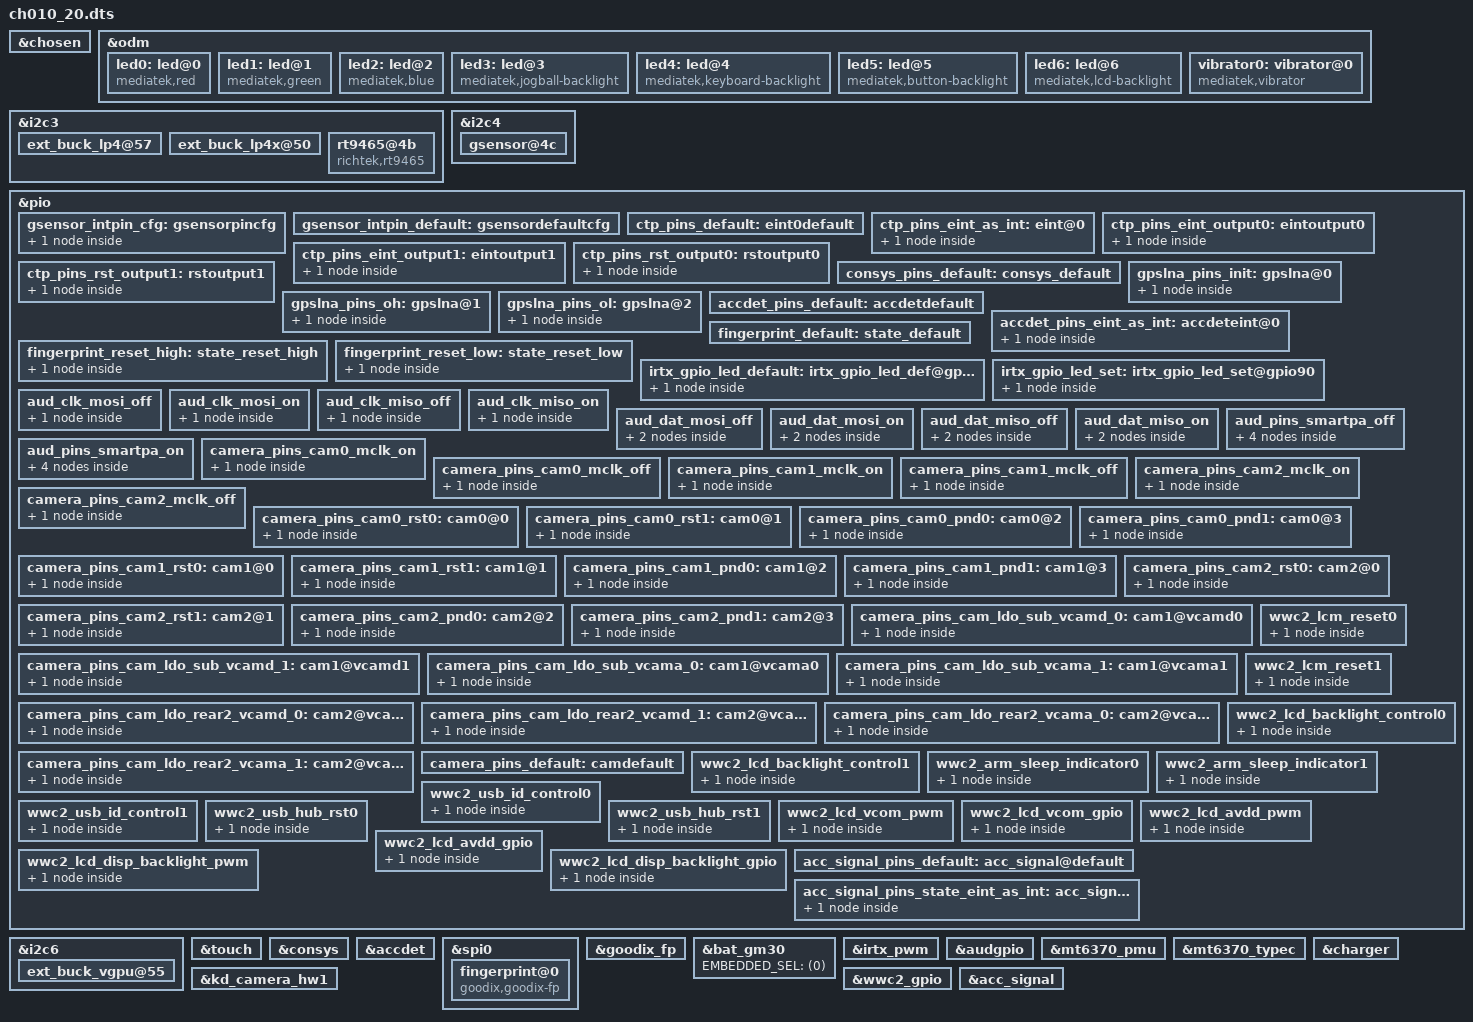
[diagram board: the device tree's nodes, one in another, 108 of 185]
#include <dt-bindings/interrupt-controller/arm-gic.h>
#include <dt-bindings/interrupt-controller/irq.h>
#include <dt-bindings/pinctrl/mt6765-pinfunc.h>
#include <dt-bindings/clock/mt6765-clk.h>

/dts-v1/;
/plugin/;

/* chosen */
&chosen {
	bootargs = "console=tty0 console=ttyS0,921600n1\
root=/dev/ram initrd=0x45000000,0x1000000 loglevel=8 \
androidboot.selinux=permissive androidboot.hardware=mt6765 \
initcall_debug=1 maxcpus=1";

	/* fpga may has no lk, we need to specify display info here */
	/* fb buffer is reserved using this dts by memory node above */
	atag,videolfb-fb_base_h = <0x0>;
	atag,videolfb-fb_base_l = <0x5e605000>;
	atag,videolfb-islcmfound = <1>;
	/* because no lk, so lcm is not inited */
	atag,videolfb-islcm_inited = <0>;
	atag,videolfb-fps= <6000>;
	atag,videolfb-vramSize= <0x017bb000>;
	atag,videolfb-lcmname= "nt35695B_fhd_dsi_cmd_auo_rt5081_drv";
};

&odm {
	led0:led@0 {
		compatible = "mediatek,red";
		led_mode = <0>;
		data = <1>;
		pwm_config = <0 0 0 0 0>;
	};
	led1:led@1 {
		compatible = "mediatek,green";
		led_mode = <0>;
		data = <1>;
		pwm_config = <0 0 0 0 0>;
	};
	led2:led@2 {
		compatible = "mediatek,blue";
		led_mode = <0>;
		data = <1>;
		pwm_config = <0 0 0 0 0>;
	};
	led3:led@3 {
		compatible = "mediatek,jogball-backlight";
		led_mode = <0>;
		data = <1>;
		pwm_config = <0 0 0 0 0>;
	};
	led4:led@4 {
		compatible = "mediatek,keyboard-backlight";
		led_mode = <0>;
		data = <1>;
		pwm_config = <0 0 0 0 0>;
	};
	led5:led@5 {
		compatible = "mediatek,button-backlight";
		led_mode = <0>;
		data = <1>;
		pwm_config = <0 0 0 0 0>;
	};
	led6:led@6 {
		compatible = "mediatek,lcd-backlight";
		led_mode = <5>;
		data = <1>;
		pwm_config = <0 3 0 0 0>;
		led_enable_gpio = <&pio 44 0>;
	};
	vibrator0:vibrator@0 {
		compatible = "mediatek,vibrator";
		vib_timer = <25>;
		vib_limit = <9>;
		vib_vol= <9>;
	};
};

&i2c3 {
	ext_buck_lp4@57 {
		regulator-name ="ext_buck_vdd2";
		regulator-min-microvolt = <300000>;
		regulator-max-microvolt = <1300000>;
		vsel_pin = <0>;
	};

	ext_buck_lp4x@50 {
		regulator-name ="ext_buck_vddq";
		regulator-min-microvolt = <300000>;
		regulator-max-microvolt = <1300000>;
		vsel_pin = <1>;
	};
};

&i2c4 {
/*  start sensor */
	gsensor@4c {
		pinctrl-names = "pin_default", "pin_cfg";
		pinctrl-0 = <&gsensor_intpin_default>;
		pinctrl-1 = <&gsensor_intpin_cfg>;
		status = "okay";

		i2c_num	= <4>;
		i2c_addr = <0x4c 0 0 0>;
		direction = <1>;
		power_id = <0xffff>;
		power_vol = <0>;
		firlen = <0>;
		is_batch_supported = <0>;
	};
/* end sensor */
};

/* sensor gpio standization */
&pio {
	gsensor_intpin_cfg: gsensorpincfg {

		pins_cmd_dat {
			pinmux = <PINMUX_GPIO4__FUNC_GPIO4>;
			slew-rate = <0>;
			bias-pull-up = <00>;
		};
	};

	gsensor_intpin_default: gsensordefaultcfg {

	};
};
/* sensor end */

&i2c6 {
	ext_buck_vgpu@55 {
		regulator-name ="ext_buck_vgpu";
		regulator-min-microvolt = <300000>;
		regulator-max-microvolt = <1300000>;
		vsel_pin = <2>;
	};
};
/* TOUCH start */
&touch {
	tpd-resolution = <1024 600>;
	use-tpd-button = <1>;
	tpd-key-num = <6>;
	tpd-key-local= <105 105 105 105 105 105>;
	tpd-key-dim-local = <1080 110 30 30 1080 180 30 30 1080 240 30 30 1080 320 30 30 1080 390 30 30 0 0 0 0>;
	tpd-max-touch-num = <6>;
	tpd-filter-enable = <1>;
	tpd-filter-pixel-density = <106>;
	tpd-filter-custom-prameters = <0 0 0 0 0 0 0 0 0 0 0 0>;
	tpd-filter-custom-speed = <0 0 0>;
	pinctrl-names = "default", "state_eint_as_int", "state_eint_output0",
		"state_eint_output1", "state_rst_output0", "state_rst_output1";
	pinctrl-0 = <&ctp_pins_default>;
	pinctrl-1 = <&ctp_pins_eint_as_int>;
	pinctrl-2 = <&ctp_pins_eint_output0>;
	pinctrl-3 = <&ctp_pins_eint_output1>;
	pinctrl-4 = <&ctp_pins_rst_output0>;
	pinctrl-5 = <&ctp_pins_rst_output1>;
	status = "okay";
};
&pio {
	ctp_pins_default: eint0default {
	};
	ctp_pins_eint_as_int: eint@0 {
		pins_cmd_dat {
			pinmux = <PINMUX_GPIO0__FUNC_GPIO0>;
			slew-rate = <0>;
			bias-disable;
		};
	};
	ctp_pins_eint_output0: eintoutput0 {
		pins_cmd_dat {
			pinmux = <PINMUX_GPIO0__FUNC_GPIO0>;
			slew-rate = <1>;
			output-low;
		};
	};
	ctp_pins_eint_output1: eintoutput1 {
		pins_cmd_dat {
			pinmux = <PINMUX_GPIO0__FUNC_GPIO0>;
			slew-rate = <1>;
			output-high;
		};
	};
	ctp_pins_rst_output0: rstoutput0 {
		pins_cmd_dat {
			pinmux = <PINMUX_GPIO174__FUNC_GPIO174>;
			slew-rate = <1>;
			output-low;
		};
	};
	ctp_pins_rst_output1: rstoutput1 {
		pins_cmd_dat {
			pinmux = <PINMUX_GPIO174__FUNC_GPIO174>;
			slew-rate = <1>;
			output-high;
		};
	};
};
/* TOUCH end */

/* CONSYS GPIO standardization */
&pio {
	consys_pins_default: consys_default {
	};
	gpslna_pins_init: gpslna@0 {
		pins_cmd_dat {
			pinmux = <PINMUX_GPIO178__FUNC_GPIO178>;
			slew-rate = <0>;
			bias-disable;
			output-low;
		};
	};
	gpslna_pins_oh: gpslna@1 {
		pins_cmd_dat {
			pinmux = <PINMUX_GPIO178__FUNC_GPIO178>;
			slew-rate = <1>;
			output-high;
		};
	};
	gpslna_pins_ol: gpslna@2 {
		pins_cmd_dat {
			pinmux = <PINMUX_GPIO178__FUNC_GPIO178>;
			slew-rate = <1>;
			output-low;
		};
	};
};
&consys {
	pinctrl-names = "default", "gps_lna_state_init",
		"gps_lna_state_oh", "gps_lna_state_ol";
	pinctrl-0 = <&consys_pins_default>;
	pinctrl-1 = <&gpslna_pins_init>;
	pinctrl-2 = <&gpslna_pins_oh>;
	pinctrl-3 = <&gpslna_pins_ol>;
	status = "okay";
};
/* CONSYS end */

/* accdet start */
&accdet {
	accdet-mic-vol = <6>;
	headset-mode-setting = <0x500 0x500 1 0x1f0 0x800 0x800 0x20 0x44>;
	accdet-plugout-debounce = <1>;
	accdet-mic-mode = <1>;
	headset-eint-level-pol = <8>;
	headset-three-key-threshold = <0 80 220 400>;
	headset-three-key-threshold-CDD = <0 121 192 600>;
	headset-four-key-threshold = <0 58 121 192 400>;
	pinctrl-names = "default", "state_eint_as_int";
	pinctrl-0 = <&accdet_pins_default>;
	pinctrl-1 = <&accdet_pins_eint_as_int>;
	status = "okay";
};
&pio {
	accdet_pins_default: accdetdefault {
	};
	accdet_pins_eint_as_int: accdeteint@0 {
		pins_cmd_dat {
			pinmux = <PINMUX_GPIO9__FUNC_GPIO9>;
			slew-rate = <0>;
			bias-disable;
		};
	};
};
/* accdet end */

/* FINGERPRINT start */
&spi0 {
	#address-cells = <1>;
	#size-cells = <0>;
	fingerprint@0 {
		compatible = "goodix,goodix-fp";
		reg = <0>;
		spi-max-frequency = <8000000>;
		netlink-event = <30>;
		status = "okay";
	};
};

&goodix_fp {
	pinctrl-names = "default", "reset_high", "reset_low";
	pinctrl-0 = <&fingerprint_default>;
	pinctrl-1 = <&fingerprint_reset_high>;
	pinctrl-2 = <&fingerprint_reset_low>;
	status = "okay";
};

&pio {
	fingerprint_default: state_default {
	};
	fingerprint_reset_high: state_reset_high {
		pins_cmd_dat {
			pinmux = <PINMUX_GPIO172__FUNC_GPIO172>;
			slew-rate = <1>;
			output-high;
		};
	};
	fingerprint_reset_low: state_reset_low {
		pins_cmd_dat {
			pinmux = <PINMUX_GPIO172__FUNC_GPIO172>;
			slew-rate = <1>;
			output-low;
		};
	};
};
/* FINGERPRINT end */

/* battery end */
&bat_gm30 {
	EMBEDDED_SEL = <(0)>;
};
/* battery end */

/* IRTX GPIO end */
&irtx_pwm {
	pinctrl-names = "irtx_gpio_led_default", "irtx_gpio_led_set";
	pinctrl-0 = <&irtx_gpio_led_default>;
	pinctrl-1 = <&irtx_gpio_led_set>;
	status = "okay";
};
&pio {
	irtx_gpio_led_default:irtx_gpio_led_def@gpio90 {
		pins_cmd_dat {
			pinmux = <PINMUX_GPIO90__FUNC_GPIO90>;
			slew-rate = <1>;
			bias-disable;
			output-low;
			input-schmitt-enable = <0>;
		};
	};

	irtx_gpio_led_set:irtx_gpio_led_set@gpio90 {
		pins_cmd_dat {
			pinmux = <PINMUX_GPIO90__FUNC_PWM0>;
			slew-rate = <1>;
			output-high;
		};
	};
};
/* IRTX GPIO Settings -End */

/* AUDIO GPIO standardization */
&audgpio {
	pinctrl-names = "aud_clk_mosi_off",
			"aud_clk_mosi_on",
			"aud_clk_miso_off",
			"aud_clk_miso_on",
			"aud_dat_mosi_off",
			"aud_dat_mosi_on",
			"aud_dat_miso_off",
			"aud_dat_miso_on",
			"aud_smartpa_off",
			"aud_smartpa_on";
	pinctrl-0 = <&aud_clk_mosi_off>;
	pinctrl-1 = <&aud_clk_mosi_on>;
	pinctrl-2 = <&aud_clk_miso_off>;
	pinctrl-3 = <&aud_clk_miso_on>;
	pinctrl-4 = <&aud_dat_mosi_off>;
	pinctrl-5 = <&aud_dat_mosi_on>;
	pinctrl-6 = <&aud_dat_miso_off>;
	pinctrl-7 = <&aud_dat_miso_on>;
	pinctrl-8 = <&aud_pins_smartpa_off>;
	pinctrl-9 = <&aud_pins_smartpa_on>;
	status = "okay";
};

&pio {
	aud_clk_mosi_off: aud_clk_mosi_off {
		pins_cmd0_dat {
			pinmux = <PINMUX_GPIO136__FUNC_GPIO136>;
		};
	};

	aud_clk_mosi_on: aud_clk_mosi_on {
		pins_cmd0_dat {
			pinmux = <PINMUX_GPIO136__FUNC_AUD_CLK_MOSI>;
		};
	};

	aud_clk_miso_off: aud_clk_miso_off {
		pins_cmd0_dat {
			pinmux = <PINMUX_GPIO140__FUNC_GPIO140>;
		};
	};

	aud_clk_miso_on: aud_clk_miso_on {
		pins_cmd0_dat {
			pinmux = <PINMUX_GPIO140__FUNC_AUD_CLK_MISO>;
		};
	};

	aud_dat_mosi_off: aud_dat_mosi_off {
		pins_cmd1_dat {
			pinmux = <PINMUX_GPIO138__FUNC_GPIO138>;
			input-enable;
			slew-rate = <0>;
			bias-disable;
		};
		pins_cmd2_dat {
			pinmux = <PINMUX_GPIO139__FUNC_GPIO139>;
			input-enable;
			slew-rate = <0>;
			bias-disable;
		};
	};

	aud_dat_mosi_on: aud_dat_mosi_on {
		pins_cmd1_dat {
			pinmux = <PINMUX_GPIO138__FUNC_AUD_DAT_MOSI0>;
		};
		pins_cmd2_dat {
			pinmux = <PINMUX_GPIO139__FUNC_AUD_DAT_MOSI1>;
		};
	};

	aud_dat_miso_off: aud_dat_miso_off {
		pins_cmd1_dat {
			pinmux = <PINMUX_GPIO142__FUNC_GPIO142>;
			input-enable;
			slew-rate = <0>;
			bias-disable;
		};
		pins_cmd2_dat {
			pinmux = <PINMUX_GPIO143__FUNC_GPIO143>;
			input-enable;
			slew-rate = <0>;
			bias-disable;
		};
	};

	aud_dat_miso_on: aud_dat_miso_on {
		pins_cmd1_dat {
			pinmux = <PINMUX_GPIO142__FUNC_AUD_DAT_MISO0>;
		};
		pins_cmd2_dat {
			pinmux = <PINMUX_GPIO143__FUNC_AUD_DAT_MISO1>;
		};
	};

	aud_pins_smartpa_off: aud_pins_smartpa_off {
		pins_cmd0_dat {
			pinmux = <PINMUX_GPIO17__FUNC_GPIO17>;
		};
		pins_cmd1_dat {
			pinmux = <PINMUX_GPIO18__FUNC_GPIO18>;
		};
		pins_cmd2_dat {
			pinmux = <PINMUX_GPIO19__FUNC_GPIO19>;
		};
		pins_cmd3_dat {
			pinmux = <PINMUX_GPIO20__FUNC_GPIO20>;
		};
	};

	aud_pins_smartpa_on: aud_pins_smartpa_on {
		pins_cmd0_dat {
			pinmux = <PINMUX_GPIO17__FUNC_I2S0_DI>;
		};
		pins_cmd1_dat {
			pinmux = <PINMUX_GPIO18__FUNC_I2S3_BCK>;
		};
		pins_cmd2_dat {
			pinmux = <PINMUX_GPIO19__FUNC_I2S3_LRCK>;
		};
		pins_cmd3_dat {
			pinmux = <PINMUX_GPIO20__FUNC_I2S3_DO>;
		};
	};
};
/* AUDIO end */

&mt6370_pmu {
	mt6370,intr_gpio_num = <11>; /* direct defined GPIO num */
	mt6370,intr_gpio = <&pio 11 0x0>;
};

&mt6370_typec {
	mt6370pd,intr_gpio_num = <41>; /* direct defined GPIO num */
	mt6370pd,intr_gpio = <&pio 41 0x0>;
};

&charger {
	algorithm_name = "DualSwitchCharging";
	chg1_ta_ac_charger_current = <2000000>;
	chg2_ta_ac_charger_current = <2000000>;
};

&i2c3 {
	rt9465@4b {
		compatible = "richtek,rt9465";
		reg = <0x4b>;
		status = "okay";
		rt,en_gpio_num = <176>;
		rt,en_gpio = <&pio 176 0x0>;
		rt,intr_gpio_num = <23>; /* direct defined GPIO num */
		rt,intr_gpio = <&pio 23 0x0>;
		interrupt-names = "wdtmri";
		charger_name = "secondary_chg";
		ichg = <1500000>; /* uA */
		mivr = <4500000>; /* uV */
		cv = <4550000>; /* uV */
		ieoc = <700000>; /* uA */
		safety_timer = <12>; /* hour */
		en_st; /* safety timer */
		/* en_te; */
		en_wdt;
	};
};

&pio {
	camera_pins_cam0_mclk_on: camera_pins_cam0_mclk_on {
		pins_cmd_dat {
			pinmux = <PINMUX_GPIO100__FUNC_CMMCLK1>;
		};
	};
	camera_pins_cam0_mclk_off: camera_pins_cam0_mclk_off {
		pins_cmd_dat {
			pinmux = <PINMUX_GPIO100__FUNC_GPIO100>;
		};
	};
	camera_pins_cam1_mclk_on: camera_pins_cam1_mclk_on {
		pins_cmd_dat {
			pinmux = <PINMUX_GPIO99__FUNC_CMMCLK0>;
		};
	};
	camera_pins_cam1_mclk_off: camera_pins_cam1_mclk_off {
		pins_cmd_dat {
			pinmux = <PINMUX_GPIO99__FUNC_GPIO99>;
		};
	};
	camera_pins_cam2_mclk_on: camera_pins_cam2_mclk_on {
		pins_cmd_dat {
			pinmux = <PINMUX_GPIO99__FUNC_CMMCLK0>;
		};
	};
	camera_pins_cam2_mclk_off: camera_pins_cam2_mclk_off {
		pins_cmd_dat {
			pinmux = <PINMUX_GPIO99__FUNC_GPIO99>;
		};
	};
	camera_pins_cam0_rst0: cam0@0 {
		pins_cmd_dat {
			pinmux = <PINMUX_GPIO102__FUNC_GPIO102>;
			slew-rate = <1>;
			output-low;
		};
	};
	camera_pins_cam0_rst1: cam0@1 {
		pins_cmd_dat {
			pinmux = <PINMUX_GPIO102__FUNC_GPIO102>;
			slew-rate = <1>;
			output-high;
		};
	};
	camera_pins_cam0_pnd0: cam0@2 {
		pins_cmd_dat {
			pinmux = <PINMUX_GPIO98__FUNC_GPIO98>;
			slew-rate = <1>;
			output-low;
		};
	};
	camera_pins_cam0_pnd1: cam0@3 {
		pins_cmd_dat {
			pinmux = <PINMUX_GPIO98__FUNC_GPIO98>;
			slew-rate = <1>;
			output-high;
		};
	};
	camera_pins_cam1_rst0: cam1@0 {
		pins_cmd_dat {
			pinmux = <PINMUX_GPIO101__FUNC_GPIO101>;
			slew-rate = <1>;
			output-low;
		};
	};
	camera_pins_cam1_rst1: cam1@1 {
		pins_cmd_dat {
			pinmux = <PINMUX_GPIO101__FUNC_GPIO101>;
			slew-rate = <1>;
			output-high;
		};
	};
	camera_pins_cam1_pnd0: cam1@2 {
		pins_cmd_dat {
			pinmux = <PINMUX_GPIO97__FUNC_GPIO97>;
			slew-rate = <1>;
			output-low;
		};
	};
	camera_pins_cam1_pnd1: cam1@3 {
		pins_cmd_dat {
			pinmux = <PINMUX_GPIO97__FUNC_GPIO97>;
			slew-rate = <1>;
			output-high;
		};
	};
	camera_pins_cam2_rst0: cam2@0 {
		pins_cmd_dat {
			pinmux = <PINMUX_GPIO101__FUNC_GPIO101>;
			slew-rate = <1>;
			output-low;
		};
	};
	camera_pins_cam2_rst1: cam2@1 {
		pins_cmd_dat {
			pinmux = <PINMUX_GPIO101__FUNC_GPIO101>;
			slew-rate = <1>;
			output-high;
		};
	};
	camera_pins_cam2_pnd0: cam2@2 {
		pins_cmd_dat {
			pinmux = <PINMUX_GPIO97__FUNC_GPIO97>;
			slew-rate = <1>;
			output-low;
		};
	};
	camera_pins_cam2_pnd1: cam2@3 {
		pins_cmd_dat {
			pinmux = <PINMUX_GPIO97__FUNC_GPIO97>;
			slew-rate = <1>;
			output-high;
		};
	};
	camera_pins_cam_ldo_sub_vcamd_0: cam1@vcamd0 {
		pins_cmd_dat {
			pinmux = <PINMUX_GPIO108__FUNC_GPIO108>;
			slew-rate = <1>;
			output-low;
		};
	};
	camera_pins_cam_ldo_sub_vcamd_1: cam1@vcamd1 {
		pins_cmd_dat {
			pinmux = <PINMUX_GPIO108__FUNC_GPIO108>;
			slew-rate = <1>;
			output-high;
		};
	};
	camera_pins_cam_ldo_sub_vcama_0: cam1@vcama0 {
		pins_cmd_dat {
			pinmux = <PINMUX_GPIO109__FUNC_GPIO109>;
			slew-rate = <1>;
			output-low;
		};
	};
	camera_pins_cam_ldo_sub_vcama_1: cam1@vcama1 {
		pins_cmd_dat {
			pinmux = <PINMUX_GPIO109__FUNC_GPIO109>;
			slew-rate = <1>;
			output-high;
		};
	};
	camera_pins_cam_ldo_rear2_vcamd_0: cam2@vcamd0 {
		pins_cmd_dat {
			pinmux = <PINMUX_GPIO108__FUNC_GPIO108>;
			slew-rate = <1>;
			output-low;
		};
	};
	camera_pins_cam_ldo_rear2_vcamd_1: cam2@vcamd1 {
		pins_cmd_dat {
			pinmux = <PINMUX_GPIO108__FUNC_GPIO108>;
			slew-rate = <1>;
			output-high;
		};
	};
	camera_pins_cam_ldo_rear2_vcama_0: cam2@vcama0 {
		pins_cmd_dat {
			pinmux = <PINMUX_GPIO109__FUNC_GPIO109>;
			slew-rate = <1>;
			output-low;
		};
	};
	camera_pins_cam_ldo_rear2_vcama_1: cam2@vcama1 {
		pins_cmd_dat {
			pinmux = <PINMUX_GPIO109__FUNC_GPIO109>;
			slew-rate = <1>;
			output-high;
		};
	};
	camera_pins_default: camdefault {
	};

};

&kd_camera_hw1 {
	pinctrl-names = "default",
			"cam0_rst0",
			"cam0_rst1",
			"cam0_pnd0",
			"cam0_pnd1",
			"cam1_rst0",
			"cam1_rst1",
			"cam1_pnd0",
			"cam1_pnd1",
			"cam2_rst0",
			"cam2_rst1",
			"cam2_pnd0",
			"cam2_pnd1",
			"cam1_vcamd_on",
			"cam1_vcamd_off",
			"cam1_vcama_on",
			"cam1_vcama_off",
			"cam2_vcamd_on",
			"cam2_vcamd_off",
			"cam2_vcama_on",
			"cam2_vcama_off",
			"cam0_mclk_on",
			"cam0_mclk_off",
			"cam1_mclk_on",
			"cam1_mclk_off",
			"cam2_mclk_on",
			"cam2_mclk_off";

	pinctrl-0 = <&camera_pins_default>;
	pinctrl-1 = <&camera_pins_cam0_rst0>;
	pinctrl-2 = <&camera_pins_cam0_rst1>;
	pinctrl-3 = <&camera_pins_cam0_pnd0>;
	pinctrl-4 = <&camera_pins_cam0_pnd1>;
	pinctrl-5 = <&camera_pins_cam1_rst0>;
	pinctrl-6 = <&camera_pins_cam1_rst1>;
	pinctrl-7 = <&camera_pins_cam1_pnd0>;
	pinctrl-8 = <&camera_pins_cam1_pnd1>;
	pinctrl-9 = <&camera_pins_cam2_rst0>;
	pinctrl-10 = <&camera_pins_cam2_rst1>;
	pinctrl-11 = <&camera_pins_cam2_pnd0>;
	pinctrl-12 = <&camera_pins_cam2_pnd1>;
	pinctrl-13 = <&camera_pins_cam_ldo_sub_vcamd_1>;
	pinctrl-14 = <&camera_pins_cam_ldo_sub_vcamd_0>;
	pinctrl-15 = <&camera_pins_cam_ldo_sub_vcama_1>;
	pinctrl-16 = <&camera_pins_cam_ldo_sub_vcama_0>;
	pinctrl-17 = <&camera_pins_cam_ldo_rear2_vcamd_1>;
	pinctrl-18 = <&camera_pins_cam_ldo_rear2_vcamd_0>;
	pinctrl-19 = <&camera_pins_cam_ldo_rear2_vcama_1>;
	pinctrl-20 = <&camera_pins_cam_ldo_rear2_vcama_0>;
	pinctrl-21 = <&camera_pins_cam0_mclk_on>;
	pinctrl-22 = <&camera_pins_cam0_mclk_off>;
	pinctrl-23 = <&camera_pins_cam1_mclk_on>;
	pinctrl-24 = <&camera_pins_cam1_mclk_off>;
	pinctrl-25 = <&camera_pins_cam2_mclk_on>;
	pinctrl-26 = <&camera_pins_cam2_mclk_off>;
	status = "okay";

};

&pio {
	wwc2_lcm_reset0: wwc2_lcm_reset0 {
		pins_cmd_dat {
			pinmux = <PINMUX_GPIO45__FUNC_GPIO45>;
			slew-rate = <1>;
			output-low;
		};
	};

	wwc2_lcm_reset1: wwc2_lcm_reset1 {
		pins_cmd_dat {
			pinmux = <PINMUX_GPIO45__FUNC_GPIO45>;
			slew-rate = <1>;
			output-high;
		};
	};

	wwc2_lcd_backlight_control0: wwc2_lcd_backlight_control0 {
		pins_cmd_dat {
			pinmux = <PINMUX_GPIO44__FUNC_GPIO44>;
			slew-rate = <1>;
			output-low;
		};
	};

	wwc2_lcd_backlight_control1: wwc2_lcd_backlight_control1 {
		pins_cmd_dat {
			pinmux = <PINMUX_GPIO44__FUNC_GPIO44>;
			slew-rate = <1>;
			output-high;
		};
	};

	wwc2_arm_sleep_indicator0: wwc2_arm_sleep_indicator0 {
		pins_cmd_dat {
			pinmux = <PINMUX_GPIO8__FUNC_GPIO8>;
			slew-rate = <1>;
			output-low;
		};
	};

	wwc2_arm_sleep_indicator1: wwc2_arm_sleep_indicator1 {
		pins_cmd_dat {
			pinmux = <PINMUX_GPIO8__FUNC_GPIO8>;
			slew-rate = <1>;
			output-high;
		};
	};

	wwc2_usb_id_control0: wwc2_usb_id_control0 {
		pins_cmd_dat {
			pinmux = <PINMUX_GPIO41__FUNC_GPIO41>;
			slew-rate = <0>;
			bias-pull-down = <00>;
		};
	};

	wwc2_usb_id_control1: wwc2_usb_id_control1 {
		pins_cmd_dat {
			pinmux = <PINMUX_GPIO41__FUNC_IDDIG>;
			slew-rate = <0>;
			bias-pull-up = <00>;
		};
	};

	wwc2_usb_hub_rst0: wwc2_usb_hub_rst0 {
		pins_cmd_dat {
			pinmux = <PINMUX_GPIO12__FUNC_GPIO12>;
			slew-rate = <1>;
			output-low;
		};
	};

	wwc2_usb_hub_rst1: wwc2_usb_hub_rst1 {
		pins_cmd_dat {
			pinmux = <PINMUX_GPIO12__FUNC_GPIO12>;
			slew-rate = <1>;
			output-high;
		};
	};

	wwc2_lcd_vcom_pwm: wwc2_lcd_vcom_pwm {
		pins_cmd_dat {
			pinmux = <PINMUX_GPIO154__FUNC_PWM5>;
		};
	};

	wwc2_lcd_vcom_gpio: wwc2_lcd_vcom_gpio {
		pins_cmd_dat {
			pinmux = <PINMUX_GPIO154__FUNC_GPIO154>;
			slew-rate = <1>;
			output-low;
		};
	};

	wwc2_lcd_avdd_pwm: wwc2_lcd_avdd_pwm {
		pins_cmd_dat {
			pinmux = <PINMUX_GPIO7__FUNC_PWM1>;
		};
	};

	wwc2_lcd_avdd_gpio: wwc2_lcd_avdd_gpio {
		pins_cmd_dat {
			pinmux = <PINMUX_GPIO7__FUNC_GPIO7>;
			slew-rate = <1>;
			output-low;
		};
	};

	wwc2_lcd_disp_backlight_pwm: wwc2_lcd_disp_backlight_pwm {
		pins_cmd_dat {
			pinmux = <PINMUX_GPIO43__FUNC_DISP_PWM>;
		};
	};

	wwc2_lcd_disp_backlight_gpio: wwc2_lcd_disp_backlight_gpio {
		pins_cmd_dat {
			pinmux = <PINMUX_GPIO43__FUNC_GPIO43>;
			slew-rate = <1>;
			output-high;
		};
	};
};

&wwc2_gpio {
	pinctrl-names = "lcm_reset0",
			"lcm_reset1",
			"lcd_backlight_control0", 
			"lcd_backlight_control1",
			"arm_sleep_indicator0", 
			"arm_sleep_indicator1",
			"usb_id_control0", 
			"usb_id_control1",
			"usb_hub_rst0", 
			"usb_hub_rst1",
			"lcd_vcom_pwm",
			"lcd_vcom_gpio",
			"lcd_avdd_pwm",
			"lcd_avdd_gpio",
			"lcd_disp_backlight_pwm",
			"lcd_disp_backlight_gpio";

	pinctrl-0 = <&wwc2_lcm_reset0>;
	pinctrl-1 = <&wwc2_lcm_reset1>;
	pinctrl-2 = <&wwc2_lcd_backlight_control0>;
	pinctrl-3 = <&wwc2_lcd_backlight_control1>;
	pinctrl-4 = <&wwc2_arm_sleep_indicator0>;
	pinctrl-5 = <&wwc2_arm_sleep_indicator1>;
	pinctrl-6 = <&wwc2_usb_id_control0>;
	pinctrl-7 = <&wwc2_usb_id_control1>;
	pinctrl-8 = <&wwc2_usb_hub_rst0>;
	pinctrl-9 = <&wwc2_usb_hub_rst1>;
	pinctrl-10 = <&wwc2_lcd_vcom_pwm>;
	pinctrl-11 = <&wwc2_lcd_vcom_gpio>;
	pinctrl-12 = <&wwc2_lcd_avdd_pwm>;
	pinctrl-13 = <&wwc2_lcd_avdd_gpio>;
	pinctrl-14 = <&wwc2_lcd_disp_backlight_pwm>;
	pinctrl-15 = <&wwc2_lcd_disp_backlight_gpio>;
	status = "okay";	
};


&pio {
    acc_signal_pins_default: acc_signal@default {
    };
    acc_signal_pins_state_eint_as_int: acc_signal@eint {
        pins_cmd_dat {
            pinmux = <PINMUX_GPIO9__FUNC_GPIO9>;
            slew-rate = <0>;
            bias-pull-up = <00>;
        };
    };
};

&acc_signal {
    pinctrl-names = "default", "state_eint_as_int";
    pinctrl-0 = <&acc_signal_pins_default>;
    pinctrl-1 = <&acc_signal_pins_state_eint_as_int>;
    status = "okay";
};

#include <ch010_20/cust.dtsi>
/*End of this file, DO NOT ADD ANYTHING HERE*/
